VERSION ""
NS_ :

BS_:

BU_: ECU_Engine DISPLAY

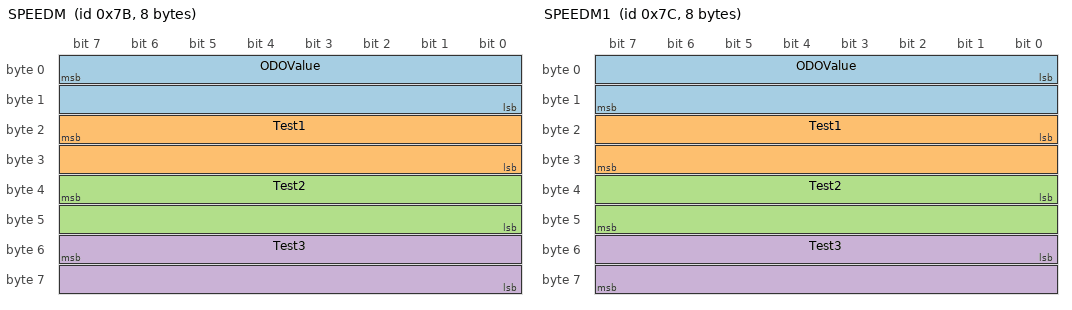
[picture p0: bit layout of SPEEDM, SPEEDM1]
BO_ 123 SPEEDM: 8 Vector__XXX
 SG_ ODOValue : 7|16@0+ (1,0) [0|65535] "m" InstrumentCluster
 SG_ Test1 : 23|16@0+ (1,0) [0|65535] "m"   InstrumentCluster
 SG_ Test2 : 39|16@0+ (1,0) [0|65535] "m"   InstrumentCluster
 SG_ Test3 : 55|16@0+ (1,0) [0|65535] "m"   InstrumentCluster

BO_ 124 SPEEDM1: 8 Vector__XXX
 SG_ ODOValue : 0|16@1+ (1,0) [0|65535] "m"  InstrumentCluster
 SG_ Test1 : 16|16@1+ (1,0) [0|65535] "m"  InstrumentCluster
 SG_ Test2 : 32|16@1+ (1,0) [0|65535] "m"  InstrumentCluster
 SG_ Test3 : 48|16@1+ (1,0) [0|65535] "m"  InstrumentCluster

CM_ "CAN Message ECU_Engine";
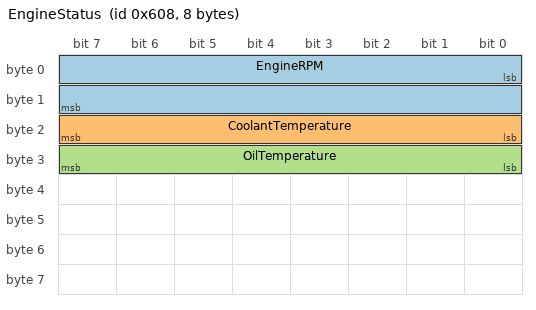
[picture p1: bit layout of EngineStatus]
BO_ 1544 EngineStatus: 8 ECU_Engine
 SG_ EngineRPM : 0|16@1+ (1,0) [0|8000] "RPM" DISPLAY
 SG_ CoolantTemperature : 16|8@1+ (1,-40) [-40|215] "C" DISPLAY
 SG_ OilTemperature : 24|8@1+ (1,-40) [-40|215] "C" DISPLAY
